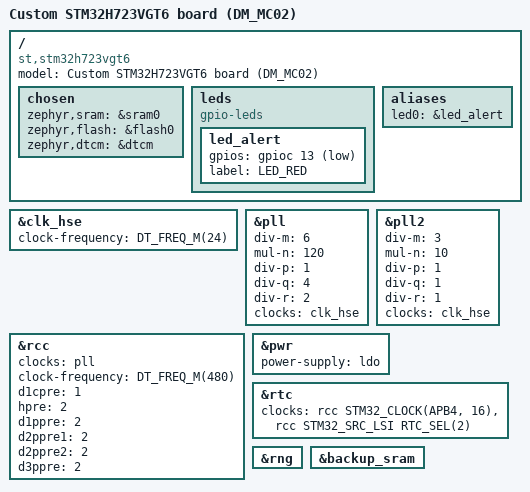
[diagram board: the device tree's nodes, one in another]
/*
 * SPDX-License-Identifier: Apache-2.0
 *
 * Custom board definition for STM32H723VGT6 (100-pin LQFP).
 * Created for the DM_MC02 robot chassis project.
 */

/dts-v1/;
#include <st/h7/stm32h723Xg.dtsi>
#include "stm32h723vgt6-pinctrl.dtsi"

/ {
	model = "Custom STM32H723VGT6 board (DM_MC02)";
	compatible = "st,stm32h723vgt6";

	chosen {
		zephyr,sram = &sram0;
		zephyr,flash = &flash0;
		zephyr,dtcm = &dtcm;
	};

	leds {
		compatible = "gpio-leds";
		led_alert: led_alert {
			gpios = <&gpioc 13 GPIO_ACTIVE_LOW>;
			label = "LED_RED";
		};
	};

	aliases {
		led0 = &led_alert;
	};
};

// &clk_hsi48 {
// 	status = "okay";
// };

&clk_hse {
	clock-frequency = <DT_FREQ_M(24)>;
	status = "okay";
};

// &clk_lse {
// 	status = "disabled";
// };

&pll {
	div-m = <6>;
	mul-n = <120>;
	div-p = <1>;
	div-q = <4>;
	div-r = <2>;
	clocks = <&clk_hse>;
	status = "okay";
};

&pll2 {
	div-m = <3>;
	mul-n = <10>;
	div-p = <1>;
	div-q = <1>;
	div-r = <1>;
	clocks = <&clk_hse>;
	status = "okay";
};

&rcc {
	clocks = <&pll>;
	clock-frequency = <DT_FREQ_M(480)>;
	d1cpre = <1>;
	hpre = <2>;
	d1ppre = <2>;
	d2ppre1 = <2>;
	d2ppre2 = <2>;
	d3ppre = <2>;
};

&pwr {
	power-supply = "ldo";
};

&rtc {
	clocks = <&rcc STM32_CLOCK(APB4, 16)>,
		 <&rcc STM32_SRC_LSI RTC_SEL(2)>;
	status = "okay";
};

&rng {
	status = "okay";
};

&backup_sram {
	status = "okay";
};
